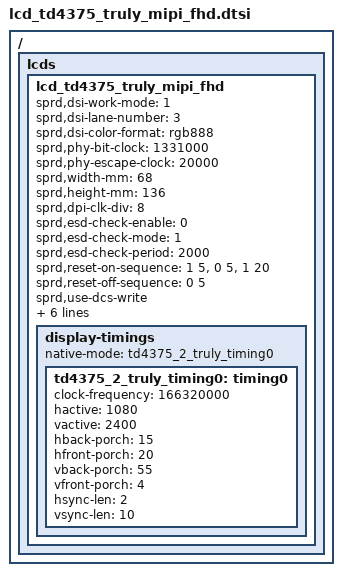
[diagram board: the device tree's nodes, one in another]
/ {
	fragment {
		target-path = "/";
		__overlay__ {
			lcds {
				lcd_td4375_truly_mipi_fhd: lcd_td4375_truly_mipi_fhd {

					sprd,dsi-work-mode = <1>; /* video burst mode*/
					sprd,dsi-lane-number = <3>;
					sprd,dsi-color-format = "rgb888";

					sprd,phy-bit-clock = <1331000>;
					sprd,phy-escape-clock = <20000>;/* kHz */

					sprd,width-mm = <68>;
					sprd,height-mm = <136>;
					sprd,dpi-clk-div = <8>;
					sprd,esd-check-enable = <0>;
					sprd,esd-check-mode = <1>;
					sprd,esd-check-period = <2000>;

					sprd,reset-on-sequence = <1 5>, <0 5>, <1 20>;
					sprd,reset-off-sequence = <0 5>;

					sprd,use-dcs-write;

					sprd,initial-command = [
						39 00 00 02 B0 00
						39 00 00 0B B6 20 6b 00 86 02 0a 13 1a 00 00
						39 00 00 05 B7 51 00 00 00
						39 00 00 08 B8 57 3d 19 be 1e 0a 0a
						39 00 00 08 B9 6f 3d 28 be 3c 14 0a
						39 00 00 08 BA b5 33 41 be 64 23 0a
						39 00 00 0C BB 44 26 c3 1f 19 06 03 c0 00 00 10
						39 00 00 0C BC 32 4c c3 52 32 1f 03 f2 00 00 13
						39 00 00 0C BD 24 68 c3 aa 3f 32 03 ff 00 00 25
						39 00 00 0D BE 00 00 00 00 00 00 00 00 00 00 00 00
						39 00 00 18 C0 00 cb 01 2c 0c 09 24 00 46 22 00 08 00 70 00 00 00 00 00 00 00 00 02
						39 00 00 35 C1 30 00 00 11 00 00 00 00 22 00 05 20 00 80 fa 40 00 84 0f 00 00 00 00 00 00 00 00 00 00 00 00 00 00 00 00 00 00 00 00 00 00 01 2c 08 08 00 00 00 00 00 00 00
						39 00 00 8e C2 00 a0 c0 02 02 00 09 05 00 00 00 00 00 00 00 00 00 00 00 00 00 00 00 00 00 00 00 00 60 b7 04 04 01 01 c1 00 a0 0a 00 00 01 08 00 00 00 00 11 00 a0 0a 04 00 00 00 00 00 00 00 00 00 00 00 00 00 00 00 00 00 00 00 00 00 11 00 00 00 00 00 00 00 00 00 00 00 00 00 00 00 00 00 00 00 00 00 00 00 11 00 00 00 00 00 00 00 00 00 00 00 00 00 00 00 00 00 00 00 00 00 00 00 11 00 00 00 00 00 00 00 00 00 00 00 00 00 00 00 00 00 00 00 00
						39 00 00 6d C3 00 00 cb 01 93 b0 01 00 00 00 00 00 cb 01 00 09 9c 00 00 00 00 00 00 00 00 00 00 00 00 00 00 00 00 00 00 00 00 00 00 00 00 00 00 00 00 00 00 00 00 00 00 00 00 00 00 00 00 00 00 00 00 00 00 aa aa 00 00 00 00 00 00 01 00 01 00 00 01 00 00 c0 00 08 00 cb 00 00 01 00 00 c0 00 00 00 00 00 00 00 00 00 00 00 00 00 00 00 00 00 00
						39 00 00 6e C4 00 00 00 00 00 00 00 45 45 4c 51 4d 4d 61 5f 5d 0f 11 44 4f 4f be bf 03 00 00 00 00 00 00 00 45 45 4c 51 4d 4d 61 5f 5d 0e 10 44 4f 4f be bf 02 ff ff ff ff ff ff 80 fe e7 80 fe e7 00 02 18 00 02 18 00 00 ff 00 00 ff 00 00 00 00 00 00 03 00 00 00 00 00 00 00 00 00 00 50 55 00 00 00 00 00 00 00 00 00 00 00 00 00 00 00 00 00 00
						39 00 00 06 C5 08 00 00 00 00
						39 00 00 3f C6 02 0a 08 10 ff ff ff 00 00 13 01 af 00 01 00 39 37 37 00 00 00 01 05 09 28 28 01 00 39 37 37 01 0b 00 00 00 1e 01 00 00 00 00 00 00 20 20 00 00 12 00 00 00 00 00 22 22 00 00 00 00 10 00
						39 00 00 0f CB 20 80 70 00 20 00 00 2d 41 00 00 00 00 ff
						39 00 00 02 CD 00
						39 00 00 24 CE 5d 40 49 53 59 5e 63 68 6e 74 7e 8a 98 a8 bb d0 e7 ff 04 00 04 04 42 40 69 5a 40 11 f4 00 00 04 fa 00 00
						39 00 00 07 CF 00 00 80 46 61 00
						39 00 00 13 D0 cc 14 d5 66 09 b0 00 cf ef e5 d4 0b 52 fe 09 09 cc 00
						39 00 00 2c D1 db db 1b b0 07 07 2A 11 31 33 31 05 33 7b 07 33 3b 78 d2 d2 06 96 13 93 22 22 22 b3 bb 80 00 bb bb 11 08 08 84 c0 09 77 ff 11 44
						39 00 00 03 D2 00 00
						39 00 00 18 D4 00 00 00 00 00 00 00 00 00 00 00 00 00 00 00 00 00 00 00 00 00 00 00
						39 00 00 4b D7 21 10 52 52 00 cb 00 46 00 cb 04 fd 01 00 03 00 05 05 00 03 04 05 00 04 08 08 02 08 06 03 08 04 08 08 0c 0b 0a 0a 0a 07 08 0a 06 00 08 08 04 05 09 00 04 04 04 04 04 04 04 02 04 04 04 04 04 04 04 04 04 04 06 06 05 05 05 00
						39 00 00 3f D8 00 12 00 00 00 00 00 00 00 00 00 00 00 00 00 00 00 00 00 00 00 00 00 00 00 00 00 00 00 00 00 00 00 00 00 00 00 00 00 00 00 00 00 00 00 00 00 00 00 00 00 00 00 00 00 00 00 00 00 00 00 00
						39 00 00 17 D9 40 99 26 ED 16 6C 16 6C 16 6C 00 14 00 14 00 14 01 0C 00 00 01 00
						39 00 00 05 DD 30 06 23 65
						39 00 00 0b DE 00 00 00 0f ff 00 00 00 00 10
						39 00 00 0b E6 00 00 00 00 00 00 00 00 00 00
						39 00 00 b7 E7 11 00 89 10 80 09 24 04 38 00 04 02 1c 02 1c 02 00 02 0e 20 00 56 00 07 0c 20 00 19 6d 18 00 10 f0 03 0c 20 00 06 0b 0b 33 0e 1c 2a 38 46 54 62 69 70 77 79 7b 7d 7e 01 02 01 00 09 40 09 be 19 fc 19 fa 19 f8 1a 38 1a 78 1a b6 2a f6 2b 34 2b 74 3b 74 6b f4 00 00 00 00 00 00 11 00 89 10 80 09 24 04 38 00 04 02 1c 02 1c 02 00 02 0e 20 00 56 00 07 0c 20 00 19 6d 18 00 10 f0 03 0c 20 00 06 0b 0b 33 0e 1c 2a 38 46 54 62 69 70 77 79 7b 7d 7e 01 02 01 00 09 40 09 be 19 fc 19 fa 19 f8 1a 38 1a 78 1a b6 2a f6 2b 34 2b 74 3b 74 6b f4 00 00 00 00 00 00
						39 00 00 05 E8 00 30 63 00
						39 00 00 1f EA 01 0e 02 e0 0a 30 00 00 09 00 02 56 00 00 00 00 00 00 00 00 04 c2 00 11 00 cb 0c b0 86 00
						39 00 00 08 EB 00 00 00 00 01 00 11
						39 00 00 0b EC 05 50 00 10 4b 0a 30 00 02 3a
						39 00 00 21 ED 01 01 02 02 08 08 09 09 00 00 00 00 02 00 00 00 00 12 02 c9 00 00 00 50 00 02 c9 00 00 a0 10 02
						39 00 00 61 EE c3 1f 00 00 00 fd 01 00 00 00 00 c2 5f 7f f0 03 00 00 00 00 00 00 00 c0 0f 7f 00 00 90 c9 09 09 c9 00 00 00 00 00 00 c0 01 00 00 00 00 c0 c0 00 00 00 00 0f 01 00 c3 1f 00 00 00 00 00 00 00 00 00 00 00 00 00 00 00 00 00 00 00 00 00 00 00 00 00 00 00 00 00 00 00 00 00 00 00 00 00 00 00 00
						39 00 00 54 EF 00 60 3d 07 40 00 00 00 00 30 30 30 00 00 00 00 00 00 00 00 00 00 60 3d 07 40 30 30 30 00 00 00 00 00 00 10 00 10 00 00 10 00 10 00 0a 0a 00 00 00 00 00 43 00 03 51 00 00 05 00 00 00 00 00 00 00 00 00 00 00 00 00 00 00 00 00 00 00 00 00 00 00 00 00
						39 00 00 09 F9 44 3f 00 8d bf 00 09 1d
						39 00 00 02 B0 03
						39 00 00 02 B0 00
						39 00 00 05 E5 03 07 00 00
						39 00 00 4d C7 00 00 01 13 01 95 01 B9 01 CD 01 CF 01 D5 01 CB 01 E2 01 AE 01 FC 01 B2 01 F0 01 A3 02 02 01 E4 02 4C 02 A3 02 AE 00 00 01 13 01 95 01 B9 01 CD 01 CF 01 D5 01 CB 01 E2 01 AE 01 FC 01 B2 01 F0 01 A3 02 02 01 E4 02 4C 02 A3 02 AE
						39 00 00 02 51 FF
						39 00 00 02 53 0C
						39 00 00 02 55 00
						39 00 00 02 B0 03
						05 78 00 01 11
						05 0a 00 01 29
						];

					sprd,sleep-in-command = [
						13 0A 00 01 28
						13 78 00 01 10
						];
					sprd,sleep-out-command = [
						13 78 00 01 11
						13 64 00 01 29
						];

					display-timings {
						native-mode = <&td4375_2_truly_timing0>;

						td4375_2_truly_timing0: timing0 {
							clock-frequency = <166320000>;
							hactive = <1080>;
							vactive = <2400>;
							hback-porch = <15>;
							hfront-porch = <20>;
							vback-porch = <55>;
							vfront-porch = <4>;
							hsync-len = <2>;
							vsync-len = <10>;
						};
					};
				};
			};
		};
	};
};
